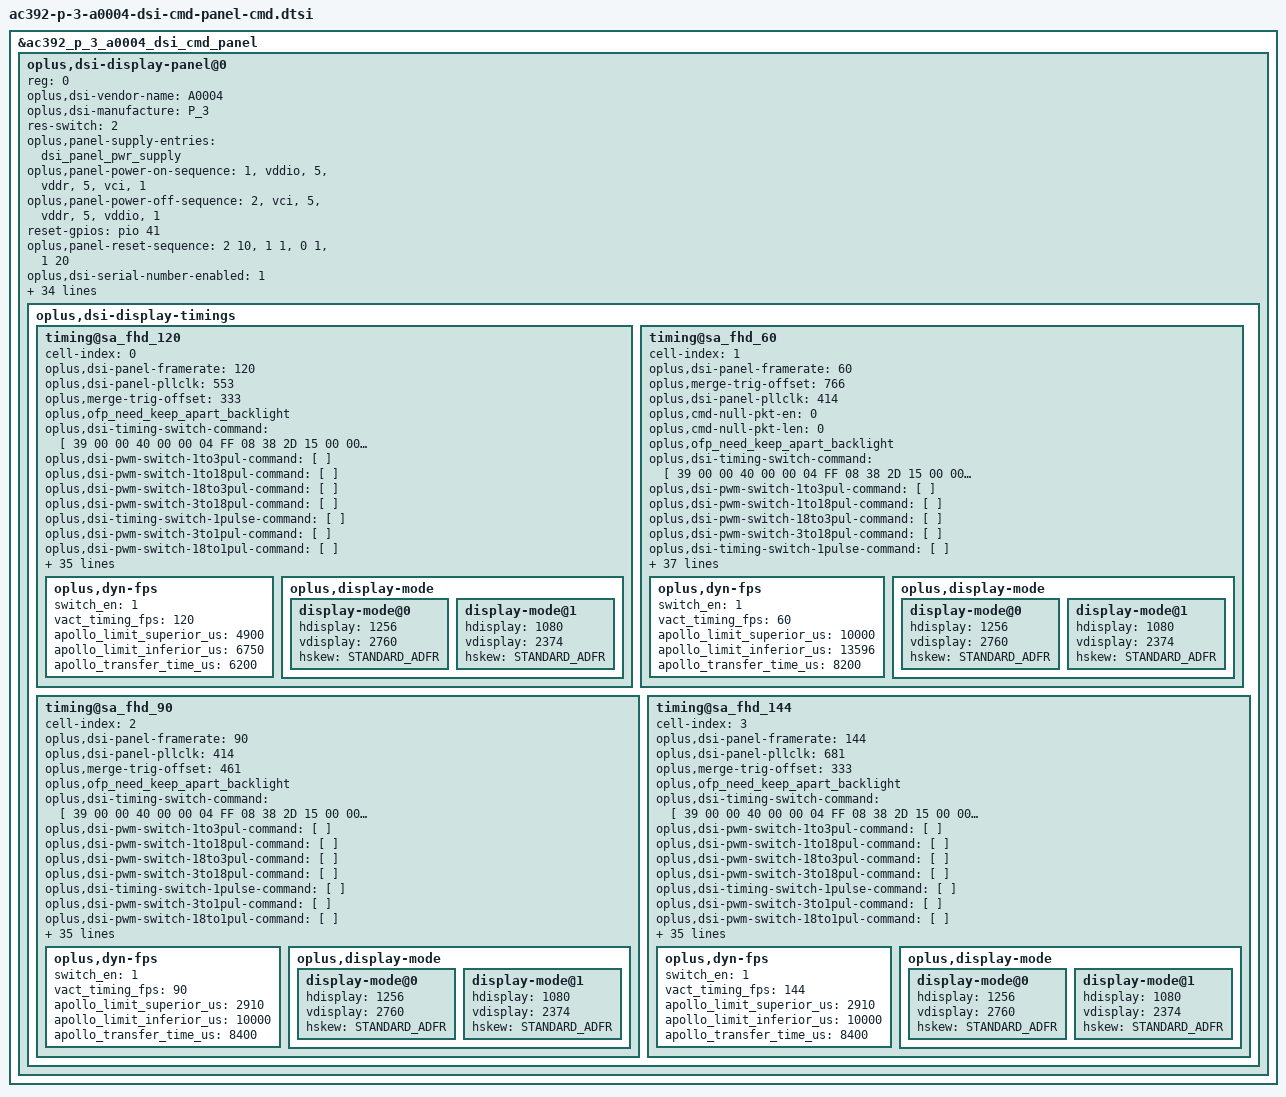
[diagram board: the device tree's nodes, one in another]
&ac392_p_3_a0004_dsi_cmd_panel {
	oplus,dsi-display-panel@0 {
		reg = <0>;
		oplus,dsi-vendor-name = "A0004";
		oplus,dsi-manufacture = "P_3";
		oplus,dsi-display-timings {
			timing@sa_fhd_120 {
				cell-index = <0>;
				oplus,dsi-panel-framerate = <120>;
				oplus,dsi-panel-pllclk = <553>;
				oplus,merge-trig-offset = <333>;
				/* OPLUS_FEATURE_DISPLAY_ONSCREENFINGERPRINT */
				oplus,ofp_need_keep_apart_backlight;
				#include "ac392-p-3-a0004-dsi-cmd-panel-common.dtsi"
				oplus,dsi-timing-switch-command = [//Switch To 120Hz normal
					39 00 00 40 00 00 04 FF 08 38 2D
					15 00 00 40 00 00 02 81 00
					39 00 00 00 00 00 04 FF 08 38 00
				];
				oplus,dsi-pwm-switch-1to3pul-command = [
				];
				oplus,dsi-pwm-switch-1to18pul-command = [
				];
				oplus,dsi-pwm-switch-18to3pul-command = [
				];
				oplus,dsi-pwm-switch-3to18pul-command = [
				];
				oplus,dsi-timing-switch-1pulse-command = [
				];
				oplus,dsi-pwm-switch-3to1pul-command = [
				];
				oplus,dsi-pwm-switch-18to1pul-command = [
				];
				oplus,dsi-on-command = [
					// ESD CHECK
					39 00 00 40 00 00 04 FF 08 38 08
					15 00 00 40 00 00 02 C8 62
					39 00 00 40 00 00 04 FF 08 38 06
					//ESD定屏卡死软解
					15 00 00 40 00 00 02 A0 00
					// 1 Bit ESD Check-Burn Code
					15 00 00 40 00 00 02 C6 01
					39 00 00 40 00 00 04 FF 08 38 08
					15 00 00 40 00 00 02 D2 05
					// DISABLE Gamma Page
					39 00 00 40 00 00 09 ED FF FF FF F7 FF FF BF FF
					39 00 00 40 00 00 09 EE FE EF C1 E0 00 C0 01 00
					//Normal mode 120hz
					39 00 00 40 00 00 04 FF 08 38 2D
					15 00 00 40 00 00 02 81 00
					//corner on
					39 00 00 40 00 00 04 FF 08 38 17
					15 00 00 40 00 00 02 A0 CC
					//hole on
					39 00 00 40 00 00 04 FF 08 38 13
					15 00 00 40 00 00 02 F9 4D
					//pps table
					39 00 00 40 00 00 04 FF 08 38 07
					15 00 00 40 00 00 02 8A 01
					39 00 00 40 00 00 03 8B 11 E0
					39 00 00 40 00 00 64 81 00 00 00 00 00 11 00 00 ab 30 80 0a c8 04 e8 00 14 02 74 02 74 02 00 02 3b 00 20 01 cc 00 08 00 0c 05 0e 04 64 18 00 11 00 07 10 20 00 06 0f 0f 33 0e 1c 2a 38 46 54 62 69 70 77 79 7b 7d 7e 02 02 22 00 2a 40 2a be 3a fc 3a fa 3a f8 3b 38 3b 78 3b b6 4b f6 4c 34 4c 74 5c 74 8c f4 00 00 00 00 00 00

					39 00 00 40 00 00 04 FF 08 38 24
					15 00 00 40 00 00 02 80 05
					15 00 00 40 00 00 02 81 1C
					39 00 00 40 00 00 04 FF 08 38 1E
					39 00 00 40 00 00 27 C5 44 00 00 22 E9 20 11 82 83 10 09 A1 00 80 63 04 50 00 04 00 44 00 00 44 00 00 44 00 00 44 00 00 44 00 00 44 00 00

					39 00 00 40 00 00 04 FF 08 38 12
					39 00 00 40 00 00 03 93 22 27
					// spr code
					39 00 00 40 00 00 04 FF 08 38 14
					39 00 00 40 00 00 09 A4 00 04 00 00 04 00 40 1A

					39 00 00 40 00 00 04 FF 08 38 00
					15 00 00 40 00 00 02 35 00
					15 00 00 40 00 00 02 53 20

					//mipi OSC 150MHz
					39 00 00 40 00 00 04 FF 08 38 20
					15 00 00 40 00 00 02 F2 00
					15 00 00 40 00 00 02 F5 2F
					15 00 00 40 00 00 02 F6 C9
					15 00 00 40 00 00 02 F7 62
					15 00 00 40 00 00 02 F2 01

					//insert black 0
					39 00 00 40 00 00 04 FF 08 38 02
					39 00 00 40 00 00 03 88 C0 00

					39 00 00 40 00 00 04 FF 08 38 08
					15 00 00 40 00 00 02 B0 55
					39 00 00 40 00 00 04 FF 08 38 1C
					39 00 00 40 00 00 03 FD 00 BD
					15 00 00 40 00 00 02 E2 01
					39 00 00 40 00 00 03 FD 00 00
					39 00 00 40 00 00 04 FF 08 38 08
					15 00 00 00 00 00 02 B0 00

					// vinit volt delay 1 frame
					39 00 00 40 00 00 04 FF 08 38 4E
					15 00 00 00 00 00 02 B1 04

					39 00 00 40 00 00 04 FF 08 38 00
					15 00 00 40 00 00 02 96 09
					15 00 00 40 00 00 02 97 CC
					15 00 00 40 00 00 02 98 02
					15 00 00 40 00 00 02 99 72
					39 00 00 40 78 00 01 11

					15 00 00 00 00 00 01 29
				];

				oplus,dsi-aod-off-command = [
					39 00 00 40 00 00 04 FF 08 38 00
					15 00 00 40 00 00 01 38
					39 00 00 00 00 00 05 51 00 00 00 00
				];
				oplus,dsi-panel-aod-off-insert-black-command = [
					39 00 00 40 00 00 04 FF 08 38 00
					39 00 00 00 00 00 02 38 00
				];
				oplus,dsi-lhbm-pressed-icon-on-command = [
					39 00 00 40 00 00 04 FF 08 38 00
					15 00 00 00 00 00 02 95 13
				];
				oplus,dsi-lhbm-pressed-icon-on-pwm-command = [

				];

				oplus,dsi-timing-switch-command-state = "dsi_hs_mode";
				oplus,dsi-pwm-switch-1to3pul-command-state = "dsi_hs_mode";
				oplus,dsi-pwm-switch-1to18pul-command-state = "dsi_hs_mode";
				oplus,dsi-pwm-switch-18to3pul-command-state = "dsi_hs_mode";
				oplus,dsi-pwm-switch-3to18pul-command-state = "dsi_hs_mode";
				oplus,dsi-timing-switch-1pulse-command-state = "dsi_hs_mode";
				oplus,dsi-pwm-switch-3to1pul-command-state = "dsi_hs_mode";
				oplus,dsi-pwm-switch-18to1pul-command-state = "dsi_hs_mode";
				oplus,dsi-on-command-state = "dsi_lp_mode";
				oplus,dsi-aod-off-command-state = "dsi_ls_mode";
				oplus,dsi-panel-aod-off-insert-black-command-state = "dsi_ls_mode";
				oplus,dsi-lhbm-pressed-icon-on-command-state = "dsi_hs_mode";
				oplus,dsi-lhbm-pressed-icon-on-pwm-command-state = "dsi_hs_mode";

				oplus,dsc-params-entries = <&dsc_params>;
				oplus,dyn-fps {
					switch_en = <1>;
					vact_timing_fps = <120>;
					apollo_limit_superior_us = <4900>;
					apollo_limit_inferior_us = <6750>;
					apollo_transfer_time_us = <6200>;
				};
				oplus,display-mode {
					display-mode@0 {
						hdisplay = <1256>;
						vdisplay = <2760>;
						hskew = <STANDARD_ADFR>;
					};
					display-mode@1 {
						hdisplay = <1080>;
						vdisplay = <2374>;
						hskew = <STANDARD_ADFR>;
					};
				};
			};

			timing@sa_fhd_60 {
				cell-index = <1>;
				oplus,dsi-panel-framerate = <60>;
				oplus,merge-trig-offset = <766>;
				oplus,dsi-panel-pllclk = <414>;
				oplus,cmd-null-pkt-en = <0>;
				oplus,cmd-null-pkt-len = <0>;
				/* OPLUS_FEATURE_DISPLAY_ONSCREENFINGERPRINT */
				oplus,ofp_need_keep_apart_backlight;
				#include "ac392-p-3-a0004-dsi-cmd-panel-common.dtsi"
				oplus,dsi-timing-switch-command = [//Switch To 60Hz normal
					39 00 00 40 00 00 04 FF 08 38 2D
					15 00 00 40 00 00 02 81 02
					39 00 00 00 00 00 04 FF 08 38 00
				];
				oplus,dsi-pwm-switch-1to3pul-command = [
				];
				oplus,dsi-pwm-switch-1to18pul-command = [
				];
				oplus,dsi-pwm-switch-18to3pul-command = [
				];
				oplus,dsi-pwm-switch-3to18pul-command = [
				];
				oplus,dsi-timing-switch-1pulse-command = [
				];
				oplus,dsi-pwm-switch-3to1pul-command = [
				];
				oplus,dsi-pwm-switch-18to1pul-command = [
				];
				oplus,dsi-on-command = [
					// ESD CHECK
					39 00 00 40 00 00 04 FF 08 38 08
					15 00 00 40 00 00 02 C8 62
					39 00 00 40 00 00 04 FF 08 38 06
					//ESD定屏卡死软解
					15 00 00 40 00 00 02 A0 00
					// 1 Bit ESD Check-Burn Code
					15 00 00 40 00 00 02 C6 01
					39 00 00 40 00 00 04 FF 08 38 08
					15 00 00 40 00 00 02 D2 05
					// DISABLE Gamma Page
					39 00 00 40 00 00 09 ED FF FF FF F7 FF FF BF FF
					39 00 00 40 00 00 09 EE FE EF C1 E0 00 C0 01 00
					//Normal mode 60hz
					39 00 00 40 00 00 04 FF 08 38 2D
					15 00 00 40 00 00 02 81 02
					//corner on
					39 00 00 40 00 00 04 FF 08 38 17
					15 00 00 40 00 00 02 A0 CC
					//hole on
					39 00 00 40 00 00 04 FF 08 38 13
					15 00 00 40 00 00 02 F9 4D
					//pps table
					39 00 00 40 00 00 04 FF 08 38 07
					15 00 00 40 00 00 02 8A 01
					39 00 00 40 00 00 03 8B 11 E0
					39 00 00 40 00 00 64 81 00 00 00 00 00 11 00 00 ab 30 80 0a c8 04 e8 00 14 02 74 02 74 02 00 02 3b 00 20 01 cc 00 08 00 0c 05 0e 04 64 18 00 11 00 07 10 20 00 06 0f 0f 33 0e 1c 2a 38 46 54 62 69 70 77 79 7b 7d 7e 02 02 22 00 2a 40 2a be 3a fc 3a fa 3a f8 3b 38 3b 78 3b b6 4b f6 4c 34 4c 74 5c 74 8c f4 00 00 00 00 00 00

					39 00 00 40 00 00 04 FF 08 38 24
					15 00 00 40 00 00 02 80 05
					15 00 00 40 00 00 02 81 1C
					39 00 00 40 00 00 04 FF 08 38 1E
					39 00 00 40 00 00 27 C5 44 00 00 22 E9 20 11 82 83 10 09 A1 00 80 63 04 50 00 04 00 44 00 00 44 00 00 44 00 00 44 00 00 44 00 00 44 00 00

					39 00 00 40 00 00 04 FF 08 38 12
					39 00 00 40 00 00 03 93 22 27
					// spr code
					39 00 00 40 00 00 04 FF 08 38 14
					39 00 00 40 00 00 09 A4 00 04 00 00 04 00 40 1A

					39 00 00 40 00 00 04 FF 08 38 00
					15 00 00 40 00 00 02 35 00
					15 00 00 40 00 00 02 53 20

					//mipi OSC 150MHz
					39 00 00 40 00 00 04 FF 08 38 20
					15 00 00 40 00 00 02 F2 00
					15 00 00 40 00 00 02 F5 2F
					15 00 00 40 00 00 02 F6 C9
					15 00 00 40 00 00 02 F7 62
					15 00 00 40 00 00 02 F2 01

					//insert black 0
					39 00 00 40 00 00 04 FF 08 38 02
					39 00 00 40 00 00 03 88 C0 00

					39 00 00 40 00 00 04 FF 08 38 08
					15 00 00 40 00 00 02 B0 55
					39 00 00 40 00 00 04 FF 08 38 1C
					39 00 00 40 00 00 03 FD 00 BD
					15 00 00 40 00 00 02 E2 01
					39 00 00 40 00 00 03 FD 00 00
					39 00 00 40 00 00 04 FF 08 38 08
					15 00 00 00 00 00 02 B0 00

					// vinit volt delay 1 frame
					39 00 00 40 00 00 04 FF 08 38 4E
					15 00 00 00 00 00 02 B1 04

					39 00 00 40 00 00 04 FF 08 38 00
					15 00 00 40 00 00 02 96 09
					15 00 00 40 00 00 02 97 CC
					15 00 00 40 00 00 02 98 02
					15 00 00 40 00 00 02 99 72
					39 00 00 40 78 00 01 11

					15 00 00 00 00 00 01 29
				];

				oplus,dsi-aod-off-command = [
					39 00 00 40 00 00 04 FF 08 38 00
					15 00 00 40 00 00 01 38
					39 00 00 00 00 00 05 51 00 00 00 00
				];
				oplus,dsi-panel-aod-off-insert-black-command = [
					39 00 00 40 00 00 04 FF 08 38 00
					39 00 00 00 00 00 02 38 00
				];
				oplus,dsi-lhbm-pressed-icon-on-command = [
					39 00 00 40 00 00 04 FF 08 38 00
					15 00 00 00 00 00 02 95 13
				];
				oplus,dsi-lhbm-pressed-icon-on-pwm-command = [

				];

				oplus,dsi-timing-switch-command-state = "dsi_hs_mode";
				oplus,dsi-pwm-switch-1to3pul-command-state = "dsi_hs_mode";
				oplus,dsi-pwm-switch-1to18pul-command-state = "dsi_hs_mode";
				oplus,dsi-pwm-switch-18to3pul-command-state = "dsi_hs_mode";
				oplus,dsi-pwm-switch-3to18pul-command-state = "dsi_hs_mode";
				oplus,dsi-timing-switch-1pulse-command-state = "dsi_hs_mode";
				oplus,dsi-pwm-switch-3to1pul-command-state = "dsi_hs_mode";
				oplus,dsi-pwm-switch-18to1pul-command-state = "dsi_hs_mode";
				oplus,dsi-on-command-state = "dsi_lp_mode";
				oplus,dsi-aod-off-command-state = "dsi_ls_mode";
				oplus,dsi-panel-aod-off-insert-black-command-state = "dsi_ls_mode";
				oplus,dsi-lhbm-pressed-icon-on-command-state = "dsi_hs_mode";
				oplus,dsi-lhbm-pressed-icon-on-pwm-command-state = "dsi_hs_mode";

				oplus,dsc-params-entries = <&dsc_params>;
				oplus,dyn-fps {
					switch_en = <1>;
					vact_timing_fps = <60>;
					apollo_limit_superior_us = <10000>;
					apollo_limit_inferior_us = <13596>;
					apollo_transfer_time_us = <8200>;
				};
				oplus,display-mode {
					display-mode@0 {
						hdisplay = <1256>;
						vdisplay = <2760>;
						hskew = <STANDARD_ADFR>;
					};
					display-mode@1 {
						hdisplay = <1080>;
						vdisplay = <2374>;
						hskew = <STANDARD_ADFR>;
					};
				};
			};

			timing@sa_fhd_90 {
				cell-index = <2>;
				oplus,dsi-panel-framerate = <90>;
				oplus,dsi-panel-pllclk = <414>;
				oplus,merge-trig-offset = <461>;
				/* OPLUS_FEATURE_DISPLAY_ONSCREENFINGERPRINT */
				oplus,ofp_need_keep_apart_backlight;
				#include "ac392-p-3-a0004-dsi-cmd-panel-common.dtsi"
				oplus,dsi-timing-switch-command = [//Switch To 90Hz normal
					39 00 00 40 00 00 04 FF 08 38 2D
					15 00 00 40 00 00 02 81 01
					39 00 00 00 00 00 04 FF 08 38 00
				];
				oplus,dsi-pwm-switch-1to3pul-command = [
				];
				oplus,dsi-pwm-switch-1to18pul-command = [
				];
				oplus,dsi-pwm-switch-18to3pul-command = [
				];
				oplus,dsi-pwm-switch-3to18pul-command = [
				];
				oplus,dsi-timing-switch-1pulse-command = [
				];
				oplus,dsi-pwm-switch-3to1pul-command = [
				];
				oplus,dsi-pwm-switch-18to1pul-command = [
				];
				oplus,dsi-on-command = [
					// ESD CHECK
					39 00 00 40 00 00 04 FF 08 38 08
					15 00 00 40 00 00 02 C8 62
					39 00 00 40 00 00 04 FF 08 38 06
					//ESD定屏卡死软解
					15 00 00 40 00 00 02 A0 00
					// 1 Bit ESD Check-Burn Code
					15 00 00 40 00 00 02 C6 01
					39 00 00 40 00 00 04 FF 08 38 08
					15 00 00 40 00 00 02 D2 05
					// DISABLE Gamma Page
					39 00 00 40 00 00 09 ED FF FF FF F7 FF FF BF FF
					39 00 00 40 00 00 09 EE FE EF C1 E0 00 C0 01 00
					//Normal mode 90hz
					39 00 00 40 00 00 04 FF 08 38 2D
					15 00 00 40 00 00 02 81 01
					//corner on
					39 00 00 40 00 00 04 FF 08 38 17
					15 00 00 40 00 00 02 A0 CC
					//hole on
					39 00 00 40 00 00 04 FF 08 38 13
					15 00 00 40 00 00 02 F9 4D
					//pps table
					39 00 00 40 00 00 04 FF 08 38 07
					15 00 00 40 00 00 02 8A 01
					39 00 00 40 00 00 03 8B 11 E0
					39 00 00 40 00 00 64 81 00 00 00 00 00 11 00 00 ab 30 80 0a c8 04 e8 00 14 02 74 02 74 02 00 02 3b 00 20 01 cc 00 08 00 0c 05 0e 04 64 18 00 11 00 07 10 20 00 06 0f 0f 33 0e 1c 2a 38 46 54 62 69 70 77 79 7b 7d 7e 02 02 22 00 2a 40 2a be 3a fc 3a fa 3a f8 3b 38 3b 78 3b b6 4b f6 4c 34 4c 74 5c 74 8c f4 00 00 00 00 00 00

					39 00 00 40 00 00 04 FF 08 38 24
					15 00 00 40 00 00 02 80 05
					15 00 00 40 00 00 02 81 1C
					39 00 00 40 00 00 04 FF 08 38 1E
					39 00 00 40 00 00 27 C5 44 00 00 22 E9 20 11 82 83 10 09 A1 00 80 63 04 50 00 04 00 44 00 00 44 00 00 44 00 00 44 00 00 44 00 00 44 00 00

					39 00 00 40 00 00 04 FF 08 38 12
					39 00 00 40 00 00 03 93 22 27
					// spr code
					39 00 00 40 00 00 04 FF 08 38 14
					39 00 00 40 00 00 09 A4 00 04 00 00 04 00 40 1A

					39 00 00 40 00 00 04 FF 08 38 00
					15 00 00 40 00 00 02 35 00
					15 00 00 40 00 00 02 53 20

					//mipi OSC 150MHz
					39 00 00 40 00 00 04 FF 08 38 20
					15 00 00 40 00 00 02 F2 00
					15 00 00 40 00 00 02 F5 2F
					15 00 00 40 00 00 02 F6 C9
					15 00 00 40 00 00 02 F7 62
					15 00 00 40 00 00 02 F2 01

					//insert black 0
					39 00 00 40 00 00 04 FF 08 38 02
					39 00 00 40 00 00 03 88 C0 00

					39 00 00 40 00 00 04 FF 08 38 08
					15 00 00 40 00 00 02 B0 55
					39 00 00 40 00 00 04 FF 08 38 1C
					39 00 00 40 00 00 03 FD 00 BD
					15 00 00 40 00 00 02 E2 01
					39 00 00 40 00 00 03 FD 00 00
					39 00 00 40 00 00 04 FF 08 38 08
					15 00 00 00 00 00 02 B0 00

					// vinit volt delay 1 frame
					39 00 00 40 00 00 04 FF 08 38 4E
					15 00 00 00 00 00 02 B1 04

					39 00 00 40 00 00 04 FF 08 38 00
					15 00 00 40 00 00 02 96 09
					15 00 00 40 00 00 02 97 CC
					15 00 00 40 00 00 02 98 02
					15 00 00 40 00 00 02 99 72
					39 00 00 40 78 00 01 11

					15 00 00 00 00 00 01 29
				];

				oplus,dsi-aod-off-command = [
					39 00 00 40 00 00 04 FF 08 38 00
					15 00 00 40 00 00 01 38
					39 00 00 00 00 00 05 51 00 00 00 00
				];
				oplus,dsi-panel-aod-off-insert-black-command = [
					39 00 00 40 00 00 04 FF 08 38 00
					39 00 00 00 00 00 02 38 00
				];
				oplus,dsi-lhbm-pressed-icon-on-command = [
					39 00 00 40 00 00 04 FF 08 38 00
					15 00 00 00 00 00 02 95 13
				];
				oplus,dsi-lhbm-pressed-icon-on-pwm-command = [

				];

				oplus,dsi-timing-switch-command-state = "dsi_hs_mode";
				oplus,dsi-pwm-switch-1to3pul-command-state = "dsi_hs_mode";
				oplus,dsi-pwm-switch-1to18pul-command-state = "dsi_hs_mode";
				oplus,dsi-pwm-switch-18to3pul-command-state = "dsi_hs_mode";
				oplus,dsi-pwm-switch-3to18pul-command-state = "dsi_hs_mode";
				oplus,dsi-timing-switch-1pulse-command-state = "dsi_hs_mode";
				oplus,dsi-pwm-switch-3to1pul-command-state = "dsi_hs_mode";
				oplus,dsi-pwm-switch-18to1pul-command-state = "dsi_hs_mode";
				oplus,dsi-on-command-state = "dsi_lp_mode";
				oplus,dsi-aod-off-command-state = "dsi_ls_mode";
				oplus,dsi-panel-aod-off-insert-black-command-state = "dsi_ls_mode";
				oplus,dsi-lhbm-pressed-icon-on-command-state = "dsi_hs_mode";
				oplus,dsi-lhbm-pressed-icon-on-pwm-command-state = "dsi_hs_mode";

				oplus,dsc-params-entries = <&dsc_params>;
				oplus,dyn-fps {
					switch_en = <1>;
					vact_timing_fps = <90>;
					apollo_limit_superior_us = <2910>;
					apollo_limit_inferior_us = <10000>;
					apollo_transfer_time_us = <8400>;
				};
				oplus,display-mode {
					display-mode@0 {
						hdisplay = <1256>;
						vdisplay = <2760>;
						hskew = <STANDARD_ADFR>;
					};
					display-mode@1 {
						hdisplay = <1080>;
						vdisplay = <2374>;
						hskew = <STANDARD_ADFR>;
					};
				};
			};

			timing@sa_fhd_144 {
				cell-index = <3>;
				oplus,dsi-panel-framerate = <144>;
				oplus,dsi-panel-pllclk = <681>;
				oplus,merge-trig-offset = <333>;
				/* OPLUS_FEATURE_DISPLAY_ONSCREENFINGERPRINT */
				oplus,ofp_need_keep_apart_backlight;
				#include "ac392-p-3-a0004-dsi-cmd-panel-common.dtsi"
				oplus,dsi-timing-switch-command = [//Switch To 144Hz normal
					39 00 00 40 00 00 04 FF 08 38 2D
					15 00 00 40 00 00 02 81 04
					39 00 00 00 00 00 04 FF 08 38 00
				];
				oplus,dsi-pwm-switch-1to3pul-command = [
				];
				oplus,dsi-pwm-switch-1to18pul-command = [
				];
				oplus,dsi-pwm-switch-18to3pul-command = [
				];
				oplus,dsi-pwm-switch-3to18pul-command = [
				];
				oplus,dsi-timing-switch-1pulse-command = [
				];
				oplus,dsi-pwm-switch-3to1pul-command = [
				];
				oplus,dsi-pwm-switch-18to1pul-command = [
				];
				oplus,dsi-on-command = [
					// ESD CHECK
					39 00 00 40 00 00 04 FF 08 38 08
					15 00 00 40 00 00 02 C8 62
					39 00 00 40 00 00 04 FF 08 38 06
					//ESD定屏卡死软解
					15 00 00 40 00 00 02 A0 00
					// 1 Bit ESD Check-Burn Code
					15 00 00 40 00 00 02 C6 01
					39 00 00 40 00 00 04 FF 08 38 08
					15 00 00 40 00 00 02 D2 05
					// DISABLE Gamma Page
					39 00 00 40 00 00 09 ED FF FF FF F7 FF FF BF FF
					39 00 00 40 00 00 09 EE FE EF C1 E0 00 C0 01 00
					//Normal mode 144hz
					39 00 00 40 00 00 04 FF 08 38 2D
					15 00 00 40 00 00 02 81 04
					// corner on
					39 00 00 40 00 00 04 FF 08 38 17
					15 00 00 40 00 00 02 A0 CC
					//hole on
					39 00 00 40 00 00 04 FF 08 38 13
					15 00 00 40 00 00 02 F9 4D
					//pps table
					39 00 00 40 00 00 04 FF 08 38 07
					15 00 00 40 00 00 02 8A 01
					39 00 00 40 00 00 03 8B 11 E0
					39 00 00 40 00 00 64 81 00 00 00 00 00 11 00 00 ab 30 80 0a c8 04 e8 00 14 02 74 02 74 02 00 02 3b 00 20 01 cc 00 08 00 0c 05 0e 04 64 18 00 11 00 07 10 20 00 06 0f 0f 33 0e 1c 2a 38 46 54 62 69 70 77 79 7b 7d 7e 02 02 22 00 2a 40 2a be 3a fc 3a fa 3a f8 3b 38 3b 78 3b b6 4b f6 4c 34 4c 74 5c 74 8c f4 00 00 00 00 00 00

					39 00 00 40 00 00 04 FF 08 38 24
					15 00 00 40 00 00 02 80 05
					15 00 00 40 00 00 02 81 1C
					39 00 00 40 00 00 04 FF 08 38 1E
					39 00 00 40 00 00 27 C5 44 00 00 22 E9 20 11 82 83 10 09 A1 00 80 63 04 50 00 04 00 44 00 00 44 00 00 44 00 00 44 00 00 44 00 00 44 00 00

					39 00 00 40 00 00 04 FF 08 38 12
					39 00 00 40 00 00 03 93 22 27
					// spr code
					39 00 00 40 00 00 04 FF 08 38 14
					39 00 00 40 00 00 09 A4 00 04 00 00 04 00 40 1A

					39 00 00 40 00 00 04 FF 08 38 00
					15 00 00 40 00 00 02 35 00
					15 00 00 40 00 00 02 53 20

					//mipi OSC 150MHz
					39 00 00 40 00 00 04 FF 08 38 20
					15 00 00 40 00 00 02 F2 00
					15 00 00 40 00 00 02 F5 2F
					15 00 00 40 00 00 02 F6 C9
					15 00 00 40 00 00 02 F7 62
					15 00 00 40 00 00 02 F2 01

					//insert black 0
					39 00 00 40 00 00 04 FF 08 38 02
					39 00 00 40 00 00 03 88 C0 00

					39 00 00 40 00 00 04 FF 08 38 08
					15 00 00 40 00 00 02 B0 55
					39 00 00 40 00 00 04 FF 08 38 1C
					39 00 00 40 00 00 03 FD 00 BD
					15 00 00 40 00 00 02 E2 01
					39 00 00 40 00 00 03 FD 00 00
					39 00 00 40 00 00 04 FF 08 38 08
					15 00 00 00 00 00 02 B0 00

					// vinit volt delay 1 frame
					39 00 00 40 00 00 04 FF 08 38 4E
					15 00 00 00 00 00 02 B1 04

					39 00 00 40 00 00 04 FF 08 38 00
					15 00 00 40 00 00 02 96 09
					15 00 00 40 00 00 02 97 CC
					15 00 00 40 00 00 02 98 02
					15 00 00 40 00 00 02 99 72
					39 00 00 40 78 00 01 11

					15 00 00 00 00 00 01 29
				];

				oplus,dsi-aod-off-command = [
					39 00 00 40 00 00 04 FF 08 38 00
					15 00 00 40 00 00 01 38
					39 00 00 00 00 00 05 51 00 00 00 00
				];
				oplus,dsi-panel-aod-off-insert-black-command = [
					39 00 00 40 00 00 04 FF 08 38 00
					39 00 00 00 00 00 02 38 00
				];
				oplus,dsi-lhbm-pressed-icon-on-command = [
					39 00 00 40 00 00 04 FF 08 38 00
					15 00 00 00 00 00 02 95 13
				];
				oplus,dsi-lhbm-pressed-icon-on-pwm-command = [

				];

				oplus,dsi-timing-switch-command-state = "dsi_hs_mode";
				oplus,dsi-pwm-switch-1to3pul-command-state = "dsi_hs_mode";
				oplus,dsi-pwm-switch-1to18pul-command-state = "dsi_hs_mode";
				oplus,dsi-pwm-switch-18to3pul-command-state = "dsi_hs_mode";
				oplus,dsi-pwm-switch-3to18pul-command-state = "dsi_hs_mode";
				oplus,dsi-timing-switch-1pulse-command-state = "dsi_hs_mode";
				oplus,dsi-pwm-switch-3to1pul-command-state = "dsi_hs_mode";
				oplus,dsi-pwm-switch-18to1pul-command-state = "dsi_hs_mode";
				oplus,dsi-on-command-state = "dsi_lp_mode";
				oplus,dsi-aod-off-command-state = "dsi_ls_mode";
				oplus,dsi-panel-aod-off-insert-black-command-state = "dsi_ls_mode";
				oplus,dsi-lhbm-pressed-icon-on-command-state = "dsi_hs_mode";
				oplus,dsi-lhbm-pressed-icon-on-pwm-command-state = "dsi_hs_mode";

				oplus,dsc-params-entries = <&dsc_params>;
				oplus,dyn-fps {
					switch_en = <1>;
					vact_timing_fps = <144>;
					apollo_limit_superior_us = <2910>;
					apollo_limit_inferior_us = <10000>;
					apollo_transfer_time_us = <8400>;
				};
				oplus,display-mode {
					display-mode@0 {
						hdisplay = <1256>;
						vdisplay = <2760>;
						hskew = <STANDARD_ADFR>;
					};
					display-mode@1 {
						hdisplay = <1080>;
						vdisplay = <2374>;
						hskew = <STANDARD_ADFR>;
					};
				};
			};
		};
	};
};

&ac392_p_3_a0004_dsi_cmd_panel {
	oplus,dsi-display-panel@0 {
		res-switch = <2>;
		/* Hardware config */
		oplus,panel-supply-entries = <&dsi_panel_pwr_supply>;
		oplus,panel-power-on-sequence = "1", "vddio", "5", "vddr", "5", "vci", "1";
		oplus,panel-power-off-sequence = "2", "vci", "5", "vddr", "5", "vddio", "1";
		reset-gpios = <&pio 41 0>;
		oplus,panel-reset-sequence = <2 10>, <1 1>, <0 1>, <1 20>;
		/* Panel config */
		oplus,dsi-serial-number-enabled=<1>;
		oplus,dsi-serial-number-switch-page;
		oplus,dsi-serial-number-index= <0>;
		oplus,dsi-serial-number-switch-page-command = <0xFF 0x08 0x38 0x1D>;
		oplus,dsi-serial-number-default-switch-page-command = <0xFF 0x08 0x38 0x00>;
		oplus,dsi-serial-number-reg= <0x81>;
		oplus,dsi-serial-number-read-count= <7>;
		oplus,dsi-serial-number-year-offset= <0>;
		oplus,mode-switch-h2l-delay;
		oplus,backlight-step-set-exit-hbm;
		oplus,backlight-check-disable;
		/* demura */
		//oplus,demura-dbv-enable;
		//oplus,demura-dbv-cfg = <1153 4095>;
		/*color*/
		oplus,color-vivid-status;
		/* ESD */
		oplus,cust-esd-check = <0>; //both check TE and reg
		oplus,esd-check-enable = <1>;
		oplus,esd_check_cmd = [
			0A
		];
		oplus,esd_check_count = [
			01
		];
		oplus,esd_check_value = [
			9C
		];
		oplus,esd_check_mask = [
			FF
		];
		/* ext_params */
		oplus,panel-type = <2>;
		oplus,keep_ulps = <1>;
		oplus,lane-swap-en = <0>;
		oplus,lane-swap = <
			MIPITX_PHY_LANE_0 MIPITX_PHY_LANE_1 MIPITX_PHY_LANE_3 MIPITX_PHY_LANE_2 MIPITX_PHY_LANE_CK MIPITX_PHY_LANE_RX
			MIPITX_PHY_LANE_0 MIPITX_PHY_LANE_1 MIPITX_PHY_LANE_3 MIPITX_PHY_LANE_2 MIPITX_PHY_LANE_CK MIPITX_PHY_LANE_RX
		>;
		oplus,lcm-color-mode = <MTK_DRM_COLOR_MODE_DISPLAY_P3>;
		oplus,output-mode = <MTK_PANEL_DSC_SINGLE_PORT>;
		oplus,panel-bpp = <10>;
		oplus,physical-width-um = <69331>;
		oplus,physical-height-um = <152352>;
		oplus,panel-support-144hz;

		/* OFP config */
		oplus,ofp-fp-type = <0x410>;
		oplus,ofp-fp-local-hbm-calibration;
		oplus,ofp-longrui-aod-config = <0x06>;
		//oplus,ofp-need-aod-off-insert-black-frame;
	};
};
